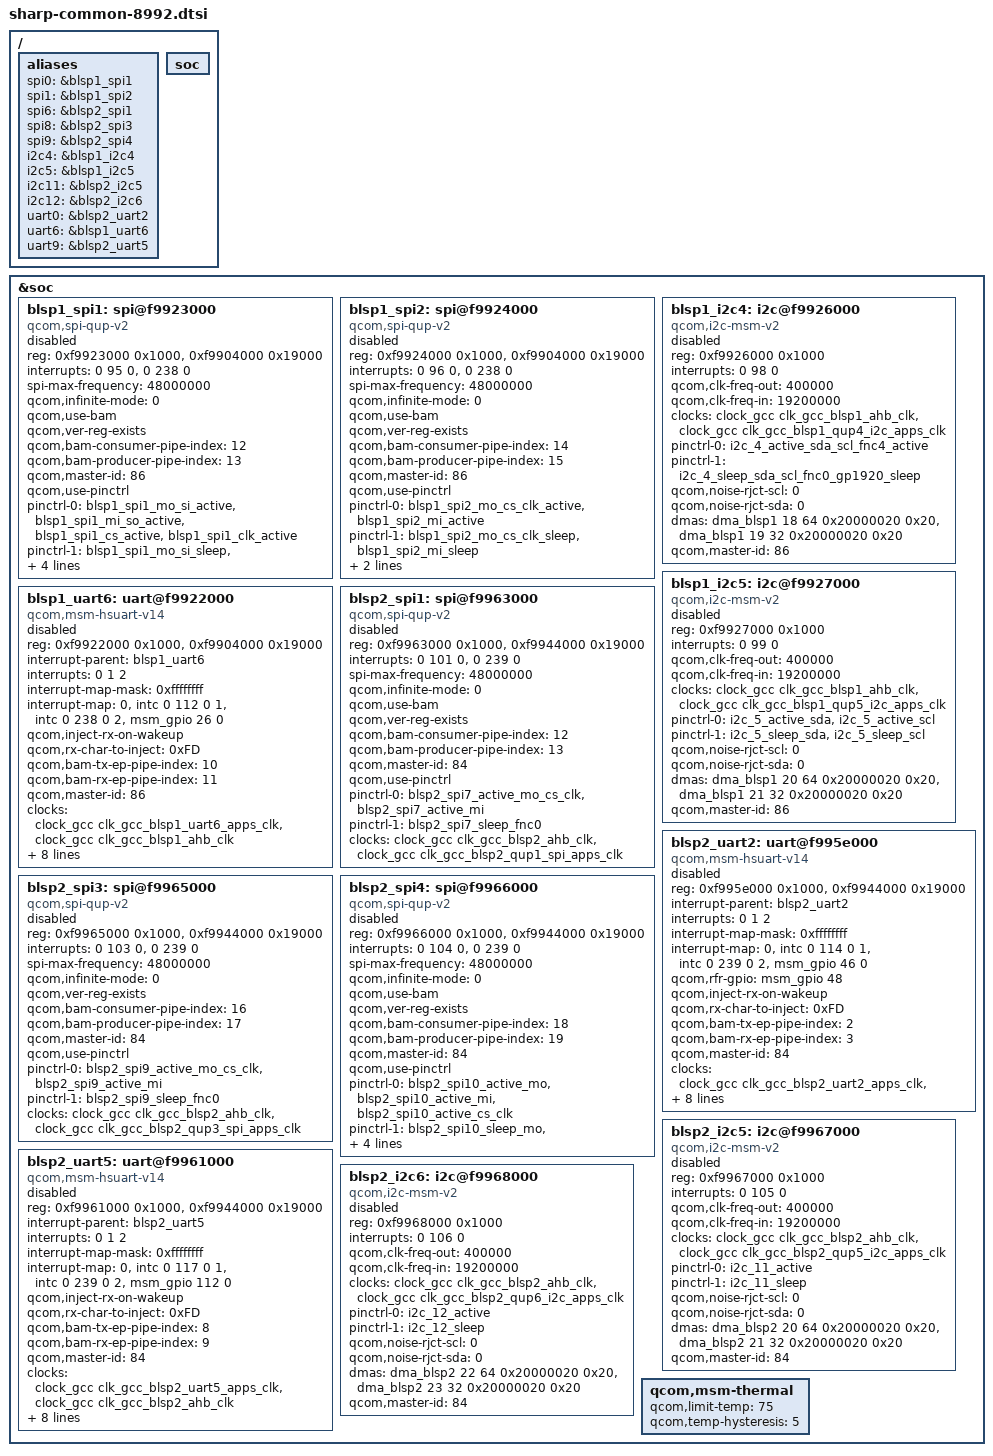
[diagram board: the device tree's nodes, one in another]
/* Copyright (c) 2015, The Linux Foundation. All rights reserved.
 *
 * This program is free software; you can redistribute it and/or modify
 * it under the terms of the GNU General Public License version 2 and
 * only version 2 as published by the Free Software Foundation.
 *
 * This program is distributed in the hope that it will be useful,
 * but WITHOUT ANY WARRANTY; without even the implied warranty of
 * MERCHANTABILITY or FITNESS FOR A PARTICULAR PURPOSE.  See the
 * GNU General Public License for more details.
 */


/*****************************************/
/*  PM8994 PMI8994                       */
/*****************************************/
#include "sharp-common-pm8994-8992.dtsi"
#include "sharp-common-pmi8994-8992.dtsi"

#include "sharp-common-sdcc-8992.dtsi"

/*----------------------------------------*/
/* Qualcomm settings.                     */
/*----------------------------------------*/
/ {
	aliases {
		spi0 = &blsp1_spi1;
		spi1 = &blsp1_spi2;
		spi6 = &blsp2_spi1;
		spi8 = &blsp2_spi3;
		spi9 = &blsp2_spi4;

		i2c4 = &blsp1_i2c4;
		i2c5 = &blsp1_i2c5;
		i2c11 = &blsp2_i2c5;
		i2c12 = &blsp2_i2c6;

		uart0 = &blsp2_uart2;
		uart6 = &blsp1_uart6;
		uart9 = &blsp2_uart5;
	};
	soc {
		/delete-node/ i2c@f9924000;
		/delete-node/ i2c@f9928000;
		/delete-node/ i2c@f9967000;
		/delete-node/ uart@f995e000;
		/delete-node/ serial@f991e000;
	};

};

/*----------------------------------------*/
/* Add SHARP settings.                    */
/*----------------------------------------*/
&soc {
	/*****************************************/
	/*  BLSP1                                */
	/*****************************************/
	/*---------------------*/
	/* BLSP1 QUP0(BLSP#1)  */
	/*---------------------*/
	blsp1_spi1: spi@f9923000 {
		compatible = "qcom,spi-qup-v2";
		#address-cells = <1>;
		#size-cells = <0>;
		reg-names = "spi_physical", "spi_bam_physical";
		reg = <0xf9923000 0x1000>,
			<0xf9904000 0x19000>;
		interrupt-names = "spi_irq", "spi_bam_irq";
		interrupts = <0 95 0>, <0 238 0>;
		spi-max-frequency = <48000000>;

		qcom,infinite-mode = <0>;
		qcom,use-bam;
		qcom,ver-reg-exists;
		qcom,bam-consumer-pipe-index = <12>;
		qcom,bam-producer-pipe-index = <13>;
		qcom,master-id = <86>;
		qcom,use-pinctrl;
		pinctrl-names = "spi_default", "spi_sleep";
		pinctrl-0 = <&blsp1_spi1_mo_si_active &blsp1_spi1_mi_so_active &blsp1_spi1_cs_active &blsp1_spi1_clk_active>;
		pinctrl-1 = <&blsp1_spi1_mo_si_sleep &blsp1_spi1_mi_so_sleep &blsp1_spi1_cs_sleep &blsp1_spi1_clk_sleep>;
		clock-names = "iface_clk", "core_clk";
		clocks = <&clock_gcc clk_gcc_blsp1_ahb_clk>,
			<&clock_gcc clk_gcc_blsp1_qup1_spi_apps_clk>;
		status = "disabled";
	};

	/*---------------------*/
	/* BLSP1 QUP1(BLSP#2)  */
	/*---------------------*/
	blsp1_spi2: spi@f9924000 {
		compatible = "qcom,spi-qup-v2";
		#address-cells = <1>;
		#size-cells = <0>;
		reg-names = "spi_physical", "spi_bam_physical";
		reg = <0xf9924000 0x1000>,
			<0xf9904000 0x19000>;
		interrupt-names = "spi_irq", "spi_bam_irq";
		interrupts = <0 96 0>, <0 238 0>;
		spi-max-frequency = <48000000>;

		qcom,infinite-mode = <0>;
		qcom,use-bam;
		qcom,ver-reg-exists;
		qcom,bam-consumer-pipe-index = <14>;
		qcom,bam-producer-pipe-index = <15>;
		qcom,master-id = <86>;
		qcom,use-pinctrl;
		pinctrl-names = "spi_default", "spi_sleep";
		pinctrl-0 = <&blsp1_spi2_mo_cs_clk_active &blsp1_spi2_mi_active>;
		pinctrl-1 = <&blsp1_spi2_mo_cs_clk_sleep &blsp1_spi2_mi_sleep>;

		clock-names = "iface_clk", "core_clk";
		clocks = <&clock_gcc clk_gcc_blsp1_ahb_clk>,
			 <&clock_gcc clk_gcc_blsp1_qup2_spi_apps_clk>;
		status = "disabled";
	};

	/*---------------------*/
	/* BLSP1 QUP2(BLSP#3)  */
	/*---------------------*/

	/*---------------------*/
	/* BLSP1 QUP3(BLSP#4)  */
	/*---------------------*/
	blsp1_i2c4: i2c@f9926000 {
		compatible = "qcom,i2c-msm-v2";
		#address-cells = <1>;
		#size-cells = <0>;
		reg-names = "qup_phys_addr";
		reg = <0xf9926000 0x1000>;
		interrupt-names = "qup_irq";
		interrupts = <0 98 0>;
		qcom,clk-freq-out = <400000>;
		qcom,clk-freq-in  = <19200000>;
		clock-names = "iface_clk", "core_clk";
		clocks = <&clock_gcc clk_gcc_blsp1_ahb_clk>,
			<&clock_gcc clk_gcc_blsp1_qup4_i2c_apps_clk>;

		pinctrl-names = "i2c_active", "i2c_sleep";
		pinctrl-0 = <&i2c_4_active_sda_scl_fnc4_active>;
		pinctrl-1 = <&i2c_4_sleep_sda_scl_fnc0_gp1920_sleep>;
		dma-names = "tx", "rx";
		qcom,noise-rjct-scl = <0>;
		qcom,noise-rjct-sda = <0>;
		dmas = <&dma_blsp1 18 64 0x20000020 0x20>,
			<&dma_blsp1 19 32 0x20000020 0x20>;
		qcom,master-id = <86>;
		status = "disabled";
	};

	/*---------------------*/
	/* BLSP1 QUP4(BLSP#5)  */
	/*---------------------*/
	blsp1_i2c5: i2c@f9927000 {
		compatible = "qcom,i2c-msm-v2";
		#address-cells = <1>;
		#size-cells = <0>;
		reg-names = "qup_phys_addr";
		reg = <0xf9927000 0x1000>;
		interrupt-names = "qup_irq";
		interrupts = <0 99 0>;
		qcom,clk-freq-out = <400000>;
		qcom,clk-freq-in  = <19200000>;
		clock-names = "iface_clk", "core_clk";
		clocks = <&clock_gcc clk_gcc_blsp1_ahb_clk>,
			<&clock_gcc clk_gcc_blsp1_qup5_i2c_apps_clk>;

		pinctrl-names = "i2c_active", "i2c_sleep";
		pinctrl-0 = <&i2c_5_active_sda &i2c_5_active_scl>;
		pinctrl-1 = <&i2c_5_sleep_sda &i2c_5_sleep_scl>;
		dma-names = "tx", "rx";
		qcom,noise-rjct-scl = <0>;
		qcom,noise-rjct-sda = <0>;
		dmas = <&dma_blsp1 20 64 0x20000020 0x20>,
			<&dma_blsp1 21 32 0x20000020 0x20>;
		qcom,master-id = <86>;
		status = "disabled";
	};

	/*---------------------*/
	/* BLSP1 QUP5(BLSP#6)  */
	/*---------------------*/
	blsp1_uart6: uart@f9922000 {
		compatible = "qcom,msm-hsuart-v14";
		reg = <0xf9922000 0x1000>,
			<0xf9904000 0x19000>;
		reg-names = "core_mem", "bam_mem";
		interrupt-names = "core_irq", "bam_irq", "wakeup_irq";
		#address-cells = <0>;
		interrupt-parent = <&blsp1_uart6>;
		interrupts = <0 1 2>;
		#interrupt-cells = <1>;
		interrupt-map-mask = <0xffffffff>;
		interrupt-map = <0 &intc 0 112 0
				1 &intc 0 238 0
				2 &msm_gpio 26 0>;

		qcom,inject-rx-on-wakeup;
		qcom,rx-char-to-inject = <0xFD>;

		qcom,bam-tx-ep-pipe-index = <10>;
		qcom,bam-rx-ep-pipe-index = <11>;
		qcom,master-id = <86>;
		clock-names = "core_clk", "iface_clk";
		clocks = <&clock_gcc clk_gcc_blsp1_uart6_apps_clk>,
			<&clock_gcc clk_gcc_blsp1_ahb_clk>;
		pinctrl-names = "sleep", "default";
		pinctrl-0 = <&hsuart6_sleep_tx &hsuart6_sleep_rx>;
		pinctrl-1 = <&hsuart6_active_tx &hsuart6_active_rx>;

		qcom,msm-bus,name = "buart6";
		qcom,msm-bus,num-cases = <2>;
		qcom,msm-bus,num-paths = <1>;
		qcom,msm-bus,vectors-KBps =
				<84 512 0 0>,
				<84 512 500 800>;
		status = "disabled";
	};


	/*****************************************/
	/*  BLSP2                                */
	/*****************************************/
	/*---------------------*/
	/* BLSP2 QUP0(BLSP#7)  */
	/*---------------------*/
	blsp2_spi1: spi@f9963000 {
		compatible = "qcom,spi-qup-v2";
		#address-cells = <1>;
		#size-cells = <0>;
		reg-names = "spi_physical", "spi_bam_physical";
		reg = <0xf9963000 0x1000>,
			<0xf9944000 0x19000>;
		interrupt-names = "spi_irq", "spi_bam_irq";
		interrupts = <0 101 0>, <0 239 0>;
		spi-max-frequency = <48000000>;

		qcom,infinite-mode = <0>;
		qcom,use-bam;
		qcom,ver-reg-exists;
		qcom,bam-consumer-pipe-index = <12>;
		qcom,bam-producer-pipe-index = <13>;
		qcom,master-id = <84>;
		qcom,use-pinctrl;
		pinctrl-names = "spi_default", "spi_sleep";
		pinctrl-0 = <&blsp2_spi7_active_mo_cs_clk &blsp2_spi7_active_mi>;
		pinctrl-1 = <&blsp2_spi7_sleep_fnc0>;

		clock-names = "iface_clk", "core_clk";
		clocks = <&clock_gcc clk_gcc_blsp2_ahb_clk>,
			<&clock_gcc clk_gcc_blsp2_qup1_spi_apps_clk>;
		status = "disabled";
	};

	/*---------------------*/
	/* BLSP2 QUP1(BLSP#8)  */
	/*---------------------*/
	blsp2_uart2: uart@f995e000 {
		compatible = "qcom,msm-hsuart-v14";
		reg = <0xf995e000 0x1000>,
			<0xf9944000 0x19000>;
		reg-names = "core_mem", "bam_mem";
		interrupt-names = "core_irq", "bam_irq", "wakeup_irq";
		#address-cells = <0>;
		interrupt-parent = <&blsp2_uart2>;
		interrupts = <0 1 2>;
		#interrupt-cells = <1>;
		interrupt-map-mask = <0xffffffff>;
		interrupt-map = <0 &intc 0 114 0
				1 &intc 0 239 0
				2 &msm_gpio 46 0>;

// Bluetooth Driver Add-S
		qcom,rfr-gpio = <&msm_gpio 48 0x00>;
// Bluetooth Driver Add-E

		qcom,inject-rx-on-wakeup;
		qcom,rx-char-to-inject = <0xFD>;

		qcom,bam-tx-ep-pipe-index = <2>;
		qcom,bam-rx-ep-pipe-index = <3>;
		qcom,master-id = <84>;
		clock-names = "core_clk", "iface_clk";
		clocks = <&clock_gcc clk_gcc_blsp2_uart2_apps_clk>,
			<&clock_gcc clk_gcc_blsp2_ahb_clk>;
		pinctrl-names = "sleep", "default";
		pinctrl-0 = <&hsuart8_sleep>;
		pinctrl-1 = <&hsuart8_active>;

		qcom,msm-bus,name = "buart8";
		qcom,msm-bus,num-cases = <2>;
		qcom,msm-bus,num-paths = <1>;
		qcom,msm-bus,vectors-KBps =
				<84 512 0 0>,
				<84 512 500 800>;
		status = "disabled";
	};

	/*---------------------*/
	/* BLSP2 QUP2(BLSP#9)  */
	/*---------------------*/
	blsp2_spi3: spi@f9965000 {
		compatible = "qcom,spi-qup-v2";
		#address-cells = <1>;
		#size-cells = <0>;
		reg-names = "spi_physical", "spi_bam_physical";
		reg = <0xf9965000 0x1000>,
			<0xf9944000 0x19000>;
		interrupt-names = "spi_irq", "spi_bam_irq";
		interrupts = <0 103 0>, <0 239 0>;
		spi-max-frequency = <48000000>;

		qcom,infinite-mode = <0>;

		qcom,ver-reg-exists;
		qcom,bam-consumer-pipe-index = <16>;
		qcom,bam-producer-pipe-index = <17>;
		qcom,master-id = <84>;
		qcom,use-pinctrl;
		pinctrl-names = "spi_default", "spi_sleep";
		pinctrl-0 = <&blsp2_spi9_active_mo_cs_clk &blsp2_spi9_active_mi>;
		pinctrl-1 = <&blsp2_spi9_sleep_fnc0>;

		clock-names = "iface_clk", "core_clk";
		clocks = <&clock_gcc clk_gcc_blsp2_ahb_clk>,
			<&clock_gcc clk_gcc_blsp2_qup3_spi_apps_clk>;
		status = "disabled";
	};

	/*---------------------*/
	/* BLSP2 QUP3(BLSP#10) */
	/*---------------------*/
	blsp2_spi4: spi@f9966000 {
		compatible = "qcom,spi-qup-v2";
		#address-cells = <1>;
		#size-cells = <0>;
		reg-names = "spi_physical", "spi_bam_physical";
		reg = <0xf9966000 0x1000>,
			<0xf9944000 0x19000>;
		interrupt-names = "spi_irq", "spi_bam_irq";
		interrupts = <0 104 0>, <0 239 0>;
		spi-max-frequency = <48000000>;

		qcom,infinite-mode = <0>;
		qcom,use-bam;
		qcom,ver-reg-exists;
		qcom,bam-consumer-pipe-index = <18>;
		qcom,bam-producer-pipe-index = <19>;
		qcom,master-id = <84>;
		qcom,use-pinctrl;
		pinctrl-names = "spi_default", "spi_sleep";
		pinctrl-0 = <&blsp2_spi10_active_mo &blsp2_spi10_active_mi &blsp2_spi10_active_cs_clk>;
		pinctrl-1 = <&blsp2_spi10_sleep_mo &blsp2_spi10_sleep_mi &blsp2_spi10_sleep_cs_clk>;

		clock-names = "iface_clk", "core_clk";
		clocks = <&clock_gcc clk_gcc_blsp2_ahb_clk>,
			 <&clock_gcc clk_gcc_blsp2_qup4_spi_apps_clk>;
		status = "disabled";
	};

	/*---------------------*/
	/* BLSP2 QUP4(BLSP#11) */
	/*---------------------*/
	blsp2_i2c5: i2c@f9967000 {
		compatible = "qcom,i2c-msm-v2";
		#address-cells = <1>;
		#size-cells = <0>;
		reg-names = "qup_phys_addr";
		reg = <0xf9967000 0x1000>;
		interrupt-names = "qup_irq";
		interrupts = <0 105 0>;
		qcom,clk-freq-out = <400000>;
		qcom,clk-freq-in  = <19200000>;
		clock-names = "iface_clk", "core_clk";
		clocks = <&clock_gcc clk_gcc_blsp2_ahb_clk>,
			<&clock_gcc clk_gcc_blsp2_qup5_i2c_apps_clk>;

		pinctrl-names = "i2c_active", "i2c_sleep";
		pinctrl-0 = <&i2c_11_active>;
		pinctrl-1 = <&i2c_11_sleep>;
		dma-names = "tx", "rx";
		qcom,noise-rjct-scl = <0>;
		qcom,noise-rjct-sda = <0>;
		dmas = <&dma_blsp2 20 64 0x20000020 0x20>,
			<&dma_blsp2 21 32 0x20000020 0x20>;
		qcom,master-id = <84>;
		status = "disabled";
	};

	blsp2_uart5: uart@f9961000 {
		compatible = "qcom,msm-hsuart-v14";
		reg = <0xf9961000 0x1000>,
			<0xf9944000 0x19000>;
		reg-names = "core_mem", "bam_mem";
		interrupt-names = "core_irq", "bam_irq", "wakeup_irq";
		#address-cells = <0>;
		interrupt-parent = <&blsp2_uart5>;
		interrupts = <0 1 2>;
		#interrupt-cells = <1>;
		interrupt-map-mask = <0xffffffff>;
		interrupt-map = <0 &intc 0 117 0
				1 &intc 0 239 0
				2 &msm_gpio 112 0>;

		qcom,inject-rx-on-wakeup;
		qcom,rx-char-to-inject = <0xFD>;

		qcom,bam-tx-ep-pipe-index = <8>;
		qcom,bam-rx-ep-pipe-index = <9>;
		qcom,master-id = <84>;
		clock-names = "core_clk", "iface_clk";
		clocks = <&clock_gcc clk_gcc_blsp2_uart5_apps_clk>,
			<&clock_gcc clk_gcc_blsp2_ahb_clk>;
		pinctrl-names = "sleep", "default";
		pinctrl-0 = <&hsuart11_sleep_tx_rx>;
		pinctrl-1 = <&hsuart11_active_tx &hsuart11_active_rx>;

		qcom,msm-bus,name = "buart11";
		qcom,msm-bus,num-cases = <2>;
		qcom,msm-bus,num-paths = <1>;
		qcom,msm-bus,vectors-KBps =
				<84 512 0 0>,
				<84 512 500 800>;
		status = "disabled";
	};

	/*---------------------*/
	/* BLSP2 QUP5(BLSP#12) */
	/*---------------------*/
	blsp2_i2c6: i2c@f9968000 {
		compatible = "qcom,i2c-msm-v2";
		#address-cells = <1>;
		#size-cells = <0>;
		reg-names = "qup_phys_addr";
		reg = <0xf9968000 0x1000>;
		interrupt-names = "qup_irq";
		interrupts = <0 106 0>;
		qcom,clk-freq-out = <400000>;
		qcom,clk-freq-in  = <19200000>;
		clock-names = "iface_clk", "core_clk";
		clocks = <&clock_gcc clk_gcc_blsp2_ahb_clk>,
			<&clock_gcc clk_gcc_blsp2_qup6_i2c_apps_clk>;

		pinctrl-names = "i2c_active", "i2c_sleep";
		pinctrl-0 = <&i2c_12_active>;
		pinctrl-1 = <&i2c_12_sleep>;
		dma-names = "tx", "rx";
		qcom,noise-rjct-scl = <0>;
		qcom,noise-rjct-sda = <0>;
		dmas = <&dma_blsp2 22 64 0x20000020 0x20>,
			<&dma_blsp2 23 32 0x20000020 0x20>;
		qcom,master-id = <84>;
		status = "disabled";
	};
	/*----------------------------------------------*/
	/* msm_thermal cpu_clock restriction thresholds */
	/*----------------------------------------------*/
	qcom,msm-thermal {
		qcom,limit-temp = <75>;
			qcom,temp-hysteresis = <5>;
	};
};
